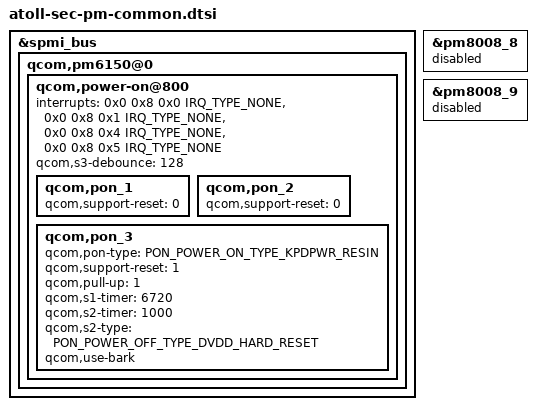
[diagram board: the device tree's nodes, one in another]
/* Copyright (c) 2020, The Linux Foundation. All rights reserved.
 *
 * This program is free software; you can redistribute it and/or modify
 * it under the terms of the GNU General Public License version 2 and
 * only version 2 as published by the Free Software Foundation.
 *
 * This program is distributed in the hope that it will be useful,
 * but WITHOUT ANY WARRANTY; without even the implied warranty of
 * MERCHANTABILITY or FITNESS FOR A PARTICULAR PURPOSE.  See the
 * GNU General Public License for more details.
 */

#include <dt-bindings/input/qcom,qpnp-power-on.h>

&spmi_bus {
	qcom,pm6150@0 {
		qcom,power-on@800 {
			interrupts = <0x0 0x8 0x0 IRQ_TYPE_NONE>,
					<0x0 0x8 0x1 IRQ_TYPE_NONE>,
					<0x0 0x8 0x4 IRQ_TYPE_NONE>,
					<0x0 0x8 0x5 IRQ_TYPE_NONE>;
			interrupt-names = "kpdpwr", "resin",
					"resin-bark", "kpdpwr-resin-bark";
			qcom,s3-debounce = <128>;

			qcom,pon_1 {
				qcom,support-reset = <0>;
			};

			qcom,pon_2 {
				qcom,support-reset = <0>;
			};

			qcom,pon_3 {
				qcom,pon-type = <PON_POWER_ON_TYPE_KPDPWR_RESIN>;
				qcom,support-reset = <1>;
				qcom,pull-up = <1>;
				qcom,s1-timer = <6720>;
				qcom,s2-timer = <1000>;
				qcom,s2-type = <PON_POWER_OFF_TYPE_DVDD_HARD_RESET>;
				qcom,use-bark;
			};
		};
	};
};

&pm8008_8 {
	status = "disabled";
};

&pm8008_9 {
	status = "disabled";
};
